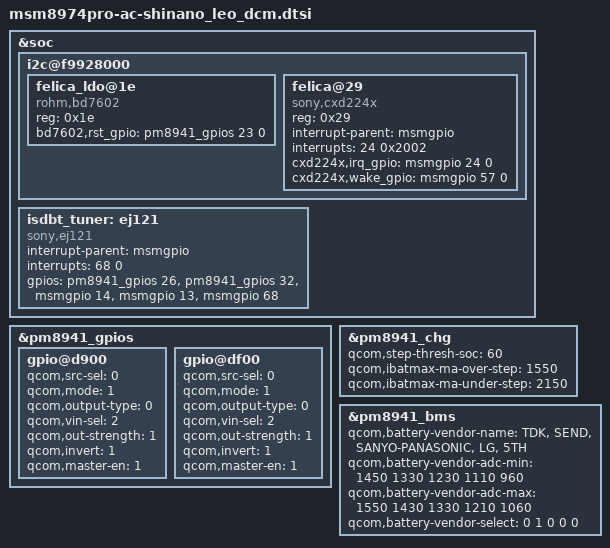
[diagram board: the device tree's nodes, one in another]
/* arch/arm/boot/dts/msm8974pro-ac-shinano_leo_dcm.dtsi
 *
 * Copyright (C) 2014 Sony Mobile Communications Inc.
 *
 * Author: Kouhei Fujiya <Kouhei.X.Fujiya@sonymobile.com>
 *
 * This program is free software; you can redistribute it and/or modify
 * it under the terms of the GNU General Public License version 2 and
 * only version 2 as published by the Free Software Foundation.
 *
 * This program is distributed in the hope that it will be useful,
 * but WITHOUT ANY WARRANTY; without even the implied warranty of
 * MERCHANTABILITY or FITNESS FOR A PARTICULAR PURPOSE.  See the
 * GNU General Public License for more details.
 *
 *
 * NOTE: This file has been modified by Sony Mobile Communications Inc.
 * Modifications are licensed under the License.
 */


&soc {
	/* I2C : BLSP6 */
	i2c@f9928000 {
		felica_ldo@1e {
			compatible = "rohm,bd7602";
			reg = <0x1e>;
			bd7602,rst_gpio = <&pm8941_gpios 23 0>;
		};
		felica@29 {
			compatible = "sony,cxd224x";
			reg = <0x29>;
			interrupt-parent = <&msmgpio>;
			interrupts = <24 0x2002>;
			cxd224x,irq_gpio = <&msmgpio 24 0>;
			cxd224x,wake_gpio = <&msmgpio 57 0>;
		};
	};

	isdbt_tuner: ej121 {
		compatible = "sony,ej121";
		interrupt-parent = <&msmgpio>;
		interrupts = <68 0>;
		gpios = <&pm8941_gpios 26 0>, /* ANT_POWER */
			<&pm8941_gpios 32 0>, /* ANT_SWITCH */
			<&msmgpio 14 0>, /* TUNER_POWER */
			<&msmgpio 13 0>, /* TUNER_RESET */
			<&msmgpio 68 0>; /* TUNER_INT */
	};
};

&pm8941_gpios {
	/* GPIO_26: TUNER_ANT_SW_EN */
	gpio@d900 {
		qcom,src-sel = <0>;		/* GPIO */
		qcom,mode = <1>;		/* Out */
		qcom,output-type = <0>;		/* CMOS */
		qcom,vin-sel = <2>;		/* S3 */
		qcom,out-strength = <1>;	/* Low */
		qcom,invert = <1>;		/* High */
		qcom,master-en = <1>;		/* Enable */
		status = "ok";
	};

	/* GPIO_32: TUNER_ANT_SW1 */
	gpio@df00 {
		qcom,src-sel = <0>;		/* GPIO */
		qcom,mode = <1>;		/* Out */
		qcom,output-type = <0>;		/* CMOS */
		qcom,vin-sel = <2>;		/* S3 */
		qcom,out-strength = <1>;	/* Low */
		qcom,invert = <1>;		/* High */
		qcom,master-en = <1>;		/* Enable */
		status = "ok";
	};
};

&pm8941_chg {
	qcom,step-thresh-soc = <60>;
	qcom,ibatmax-ma-over-step = <1550>;
	qcom,ibatmax-ma-under-step = <2150>;
};

&pm8941_bms {
	qcom,battery-vendor-name = "TDK", "SEND", "SANYO-PANASONIC", "LG", "5TH";
	qcom,battery-vendor-adc-min = <1450 1330 1230 1110 960>;
	qcom,battery-vendor-adc-max = <1550 1430 1330 1210 1060>;
	qcom,battery-vendor-select = <0 1 0 0 0>;
};
